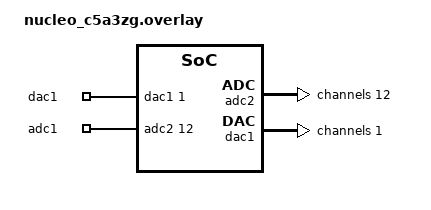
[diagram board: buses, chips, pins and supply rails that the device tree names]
/*
 * Copyright (c) 2026 STMicroelectronics
 *
 * SPDX-License-Identifier: Apache-2.0
 */

/*
 * DAC output on ARDUINO PA2
 * ADC input read from ARDUINO PA0
 * Add a cable between those two pins to run this test.
 */

/ {
	zephyr,user {
		io-channels = <&dac1 1 &adc2 12>;
		io-channel-names = "dac1", "adc1";
	};
};

&adc2 {
	#address-cells = <1>;
	#size-cells = <0>;

	channel@c {
		reg = <12>;
		zephyr,gain = "ADC_GAIN_1";
		zephyr,reference = "ADC_REF_INTERNAL";
		zephyr,resolution = <12>;
		zephyr,acquisition-time = <ADC_ACQ_TIME_MAX>;
	};
};

&dac1 {
	#address-cells = <1>;
	#size-cells = <0>;

	channel@1 {
		reg = <1>;
		zephyr,resolution = <12>;
	};
};
